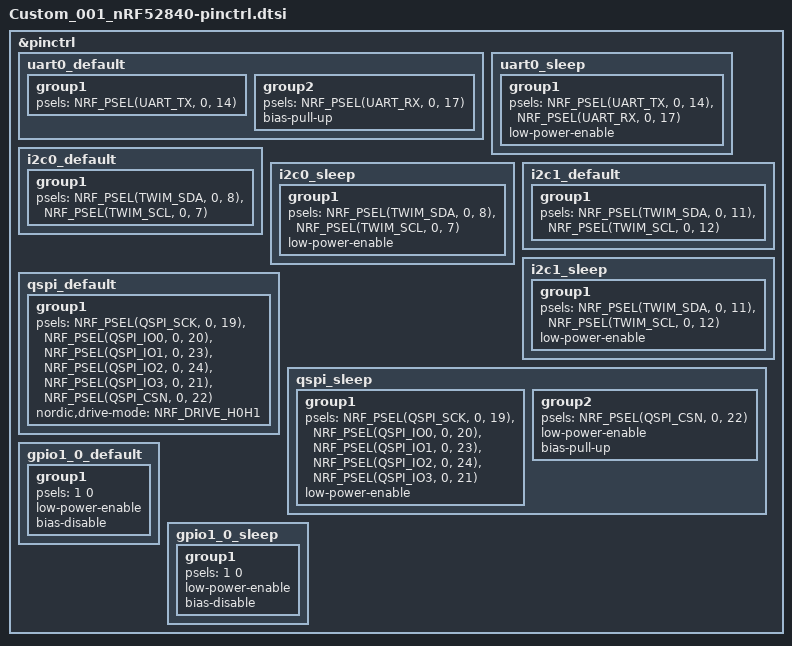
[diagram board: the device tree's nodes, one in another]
&pinctrl {
    uart0_default: uart0_default {
        group1 {
            psels = <NRF_PSEL(UART_TX, 0, 14)>;
        };
        group2 {
            psels = <NRF_PSEL(UART_RX, 0, 17)>;
            bias-pull-up;
        };
    };

    uart0_sleep: uart0_sleep {
        group1 {
            psels = <NRF_PSEL(UART_TX, 0, 14)>,
                    <NRF_PSEL(UART_RX, 0, 17)>;
            low-power-enable;
        };
    };

	i2c0_default: i2c0_default {
		group1 {
			psels = <NRF_PSEL(TWIM_SDA, 0, 8)>,
				<NRF_PSEL(TWIM_SCL, 0, 7)>;
		};
	};

	i2c0_sleep: i2c0_sleep {
		group1 {
			psels = <NRF_PSEL(TWIM_SDA, 0, 8)>,
				<NRF_PSEL(TWIM_SCL, 0, 7)>;
			low-power-enable;
		};
	};

    i2c1_default: i2c1_default {
		group1 {
			psels = <NRF_PSEL(TWIM_SDA, 0, 11)>,
				<NRF_PSEL(TWIM_SCL, 0, 12)>;
		};
	};

	i2c1_sleep: i2c1_sleep {
		group1 {
			psels = <NRF_PSEL(TWIM_SDA, 0, 11)>,
				<NRF_PSEL(TWIM_SCL, 0, 12)>;
			low-power-enable;
		};
	};

    qspi_default: qspi_default {
		group1 {
			psels = <NRF_PSEL(QSPI_SCK, 0, 19)>,
				<NRF_PSEL(QSPI_IO0, 0, 20)>,
				<NRF_PSEL(QSPI_IO1, 0, 23)>,
				<NRF_PSEL(QSPI_IO2, 0, 24)>,
				<NRF_PSEL(QSPI_IO3, 0, 21)>,
				<NRF_PSEL(QSPI_CSN, 0, 22)>;
			nordic,drive-mode = <NRF_DRIVE_H0H1>;
		};
	};

	qspi_sleep: qspi_sleep {
		group1 {
			psels = <NRF_PSEL(QSPI_SCK, 0, 19)>,
				<NRF_PSEL(QSPI_IO0, 0, 20)>,
				<NRF_PSEL(QSPI_IO1, 0, 23)>,
				<NRF_PSEL(QSPI_IO2, 0, 24)>,
				<NRF_PSEL(QSPI_IO3, 0, 21)>;
			low-power-enable;
		};
		group2 {
			psels = <NRF_PSEL(QSPI_CSN, 0, 22)>;
			low-power-enable;
			bias-pull-up;
		};
	};

	gpio1_0_default: gpio1_0_default {
        group1 {
            psels = <1 0>;
			low-power-enable;
            bias-disable;
        };
    };

    gpio1_0_sleep: gpio1_0_sleep {
        group1 {
            psels = <1 0>;
            low-power-enable;
            bias-disable;
        };
    };

};
